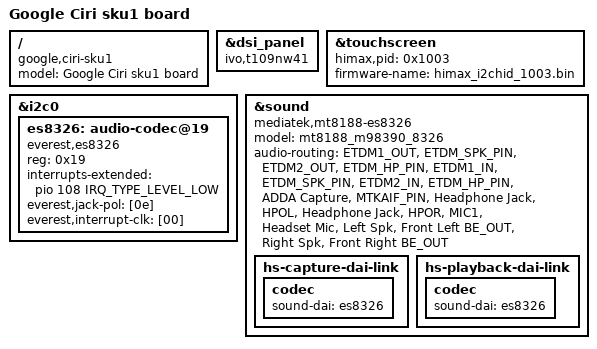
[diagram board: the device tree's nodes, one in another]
// SPDX-License-Identifier: (GPL-2.0 OR MIT)
/*
 * Copyright 2023 Google LLC
 */
/dts-v1/;
#include "mt8188-geralt-ciri.dtsi"

/ {
	model = "Google Ciri sku1 board";
	compatible = "google,ciri-sku1", "google,ciri", "mediatek,mt8188";
};

&dsi_panel {
	compatible = "ivo,t109nw41", "himax,hx83102";
};

&touchscreen {
	himax,pid = <0x1003>;
	firmware-name = "himax_i2chid_1003.bin";
};

&i2c0 {
	/delete-node/ audio-codec@1a;

	es8326: audio-codec@19 {
		compatible = "everest,es8326";
		reg = <0x19>;
		interrupts-extended = <&pio 108 IRQ_TYPE_LEVEL_LOW>;
		#sound-dai-cells = <0>;
		everest,jack-pol = [0e];
		everest,interrupt-clk = [00];
	};
};

&sound {
	compatible = "mediatek,mt8188-es8326";
	model = "mt8188_m98390_8326";

	audio-routing =
		"ETDM1_OUT", "ETDM_SPK_PIN",
		"ETDM2_OUT", "ETDM_HP_PIN",
		"ETDM1_IN", "ETDM_SPK_PIN",
		"ETDM2_IN", "ETDM_HP_PIN",
		"ADDA Capture", "MTKAIF_PIN",
		"Headphone Jack", "HPOL",
		"Headphone Jack", "HPOR",
		"MIC1", "Headset Mic",
		"Left Spk", "Front Left BE_OUT",
		"Right Spk", "Front Right BE_OUT";
	status = "okay";

	hs-capture-dai-link {
		codec {
			sound-dai = <&es8326>;
		};
	};

	hs-playback-dai-link {
		codec {
			sound-dai = <&es8326>;
		};
	};
};
